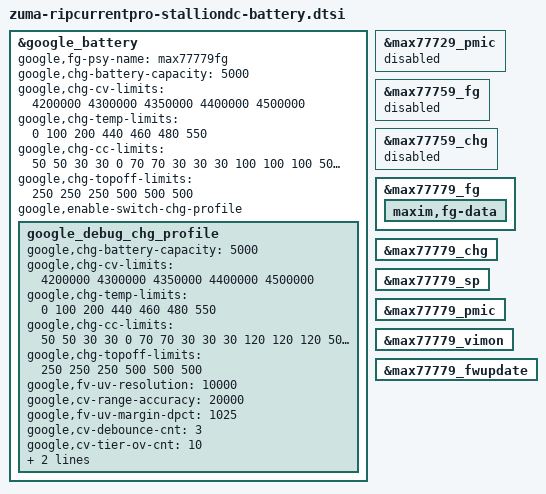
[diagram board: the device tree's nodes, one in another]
// SPDX-License-Identifier: GPL-2.0-only
/*
 * Battery device tree entries for ripcurrentpro + Stallion DC
 *
 * Copyright 2024 Google LLC
 *
 */

#include "zuma/zuma-max777xx_fwupdate.dtsi"

&google_battery {
	google,fg-psy-name = "max77779fg";

	/* tegu EVT charge table */

	google,chg-battery-capacity = <5000>;

	google,chg-cv-limits = <4200000 4300000 4350000 4400000 4500000>;
	google,chg-temp-limits = <0 100 200 440 460 480 550>;
	google,chg-cc-limits = <
		 50   50   30   30    0
		 70   70   30   30   30
		100  100  100   50   50
		 90   90   90   50   50
		 50   50    0    0    0
		 30    0    0    0    0
	>;

	google,chg-topoff-limits = <250 250 250 500 500 500>;

	google,enable-switch-chg-profile;

	google_debug_chg_profile {
		google,chg-battery-capacity = <5000>;
		google,chg-cv-limits = <4200000 4300000 4350000 4400000 4500000>;
		google,chg-temp-limits = <0 100 200 440 460 480 550>;
		google,chg-cc-limits = <
			 50   50   30   30    0
			 70   70   30   30   30
			120  120  120   50   50
			 90   90   90   50   50
			 50   50    0    0    0
			 30    0    0    0    0
		>;
		google,chg-topoff-limits = <250 250 250 500 500 500>;

		google,fv-uv-resolution = <10000>;
		google,cv-range-accuracy = <20000>;
		google,fv-uv-margin-dpct = <1025>;
		google,cv-debounce-cnt = <3>;
		google,cv-tier-ov-cnt = <10>;
		google,cv-tier-switch-cnt = <3>;
		google,cv-otv-margin = <12000>;
	};
};

&max77729_pmic {
	status = "disabled";
};

&max77759_fg {
	status = "disabled";
};

&max77759_chg {
	status = "disabled";
};

&max77779_fg {
	status = "okay";
};

&max77779_chg {
	status = "okay";
};

&max77779_sp {
	status = "okay";
};

&max77779_pmic {
	status = "okay";
};

&max77779_fg {
	maxim,fg-data {
		#include "zuma-stallion-battery-data.dtsi"
	};
};

&max77779_vimon {
	status = "okay";
};

&max77779_fwupdate {
	status = "okay";
};
